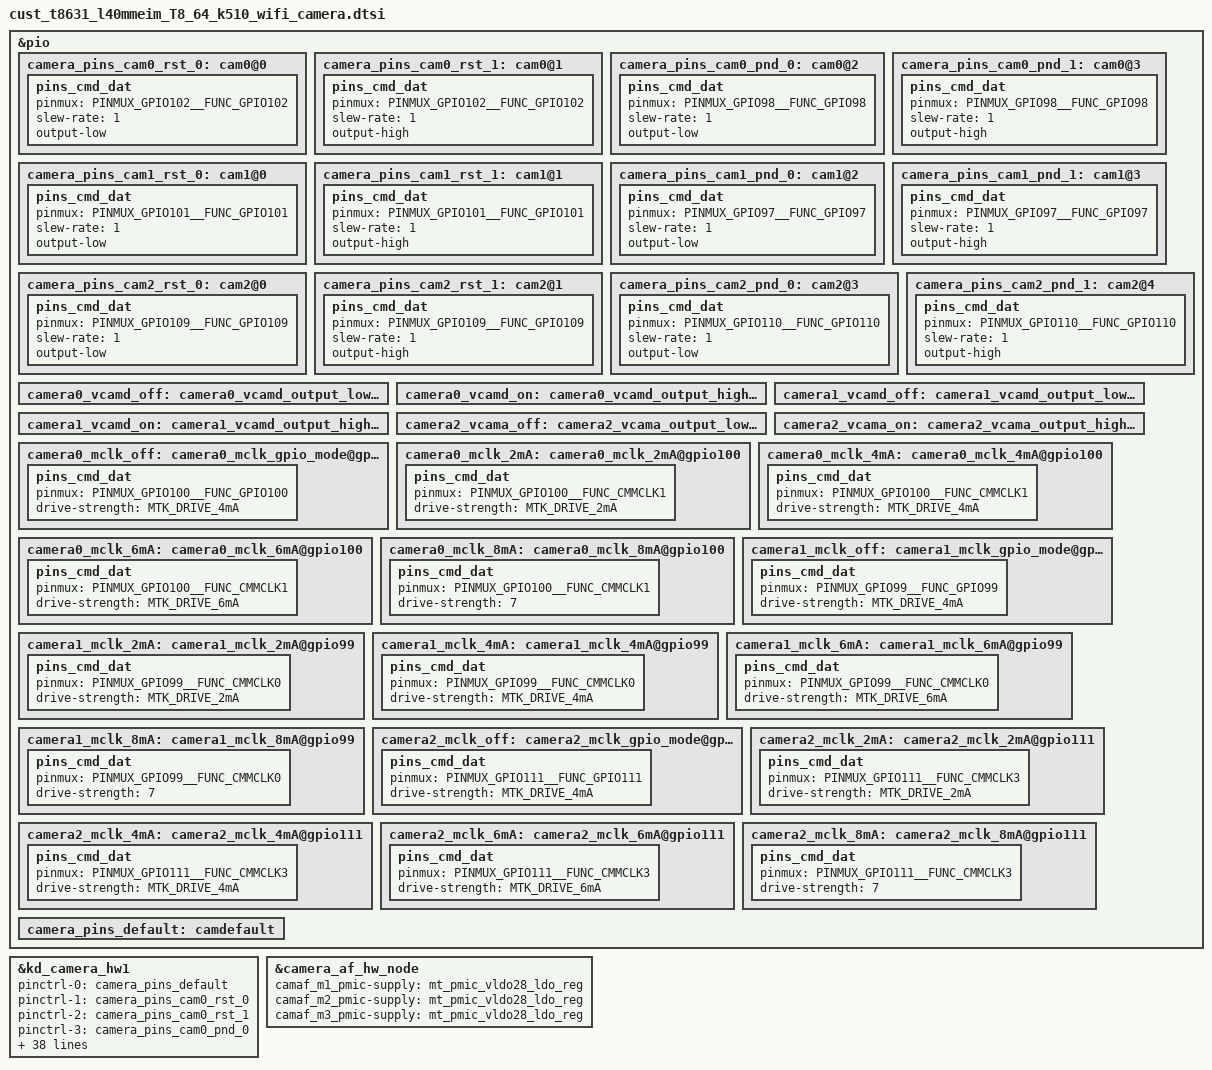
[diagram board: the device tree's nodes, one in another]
// SPDX-License-Identifier: (GPL-2.0 OR MIT)
/*
 * Copyright (c) 2019 MediaTek Inc.
 */
/* CAMERA GPIO standardization */
&pio {
	camera_pins_cam0_rst_0: cam0@0 {
		pins_cmd_dat {
			pinmux = <PINMUX_GPIO102__FUNC_GPIO102>;
			slew-rate = <1>;
			output-low;
		};
	};
	camera_pins_cam0_rst_1: cam0@1 {
		pins_cmd_dat {
			pinmux = <PINMUX_GPIO102__FUNC_GPIO102>;
			slew-rate = <1>;
			output-high;
		};
	};
	camera_pins_cam0_pnd_0: cam0@2 {
		pins_cmd_dat {
			pinmux = <PINMUX_GPIO98__FUNC_GPIO98>;
			slew-rate = <1>;
			output-low;
		};
	};
	camera_pins_cam0_pnd_1: cam0@3 {
		pins_cmd_dat {
			pinmux = <PINMUX_GPIO98__FUNC_GPIO98>;
			slew-rate = <1>;
			output-high;
		};
	};
	camera_pins_cam1_rst_0: cam1@0 {
		pins_cmd_dat {
			pinmux = <PINMUX_GPIO101__FUNC_GPIO101>;
			slew-rate = <1>;
			output-low;
		};
	};
	camera_pins_cam1_rst_1: cam1@1 {
		pins_cmd_dat {
			pinmux = <PINMUX_GPIO101__FUNC_GPIO101>;
			slew-rate = <1>;
			output-high;
		};
	};
	camera_pins_cam1_pnd_0: cam1@2 {
		pins_cmd_dat {
			pinmux = <PINMUX_GPIO97__FUNC_GPIO97>;
			slew-rate = <1>;
			output-low;
		};
	};
	camera_pins_cam1_pnd_1: cam1@3 {
		pins_cmd_dat {
			pinmux = <PINMUX_GPIO97__FUNC_GPIO97>;
			slew-rate = <1>;
			output-high;
		};
	};
	camera_pins_cam2_rst_0: cam2@0 {
		pins_cmd_dat {
			pinmux = <PINMUX_GPIO109__FUNC_GPIO109>;
			slew-rate = <1>;
			output-low;
		};
		
	};
	camera_pins_cam2_rst_1: cam2@1 {
		pins_cmd_dat {
			pinmux = <PINMUX_GPIO109__FUNC_GPIO109>;
			slew-rate = <1>;
			output-high;
		};
	
	};
	camera_pins_cam2_pnd_0: cam2@3 {
		pins_cmd_dat {
			pinmux = <PINMUX_GPIO110__FUNC_GPIO110>;
			slew-rate = <1>;
			output-low;
		};
	};
	camera_pins_cam2_pnd_1: cam2@4 {
		pins_cmd_dat {
			pinmux = <PINMUX_GPIO110__FUNC_GPIO110>;
			slew-rate = <1>;
			output-high;
		};
	};
	//
	
	
	camera0_vcamd_off: camera0_vcamd_output_low@gpio178 {
		//pins_cmd_dat {
			//pinmux = <PINMUX_GPIO178__FUNC_GPIO178>;
			//output-low;
		//};
	};
	camera0_vcamd_on: camera0_vcamd_output_high@gpio178 {
		//pins_cmd_dat {
			//pinmux = <PINMUX_GPIO178__FUNC_GPIO178>;
			//output-high;
		//};
	};
	camera1_vcamd_off: camera1_vcamd_output_low@gpio179 {
		//pins_cmd_dat {
			//pinmux = <PINMUX_GPIO179__FUNC_GPIO179>;
			//output-low;
		//};
	};
	camera1_vcamd_on: camera1_vcamd_output_high@gpio179 {
		//pins_cmd_dat {
			//pinmux = <PINMUX_GPIO179__FUNC_GPIO179>;
			//output-high;
		//};
	};
	camera2_vcama_off: camera2_vcama_output_low@gpio107 {
		//pins_cmd_dat {
			//pinmux = <PINMUX_GPIO107__FUNC_GPIO107>;
			//output-low;
		//};
	};
	camera2_vcama_on: camera2_vcama_output_high@gpio107 {
		//pins_cmd_dat {
			//pinmux = <PINMUX_GPIO107__FUNC_GPIO107>;
			//output-high;
		//};
	};
	
	
	//
	camera0_mclk_off: camera0_mclk_gpio_mode@gpio100 {
		pins_cmd_dat {
			pinmux = <PINMUX_GPIO100__FUNC_GPIO100>;
			drive-strength = <MTK_DRIVE_4mA>;
		};
	};
	camera0_mclk_2mA: camera0_mclk_2mA@gpio100 {
		pins_cmd_dat {
			pinmux = <PINMUX_GPIO100__FUNC_CMMCLK1>;
			drive-strength = <MTK_DRIVE_2mA>;
		};
	};
	camera0_mclk_4mA: camera0_mclk_4mA@gpio100 {
		pins_cmd_dat {
			pinmux = <PINMUX_GPIO100__FUNC_CMMCLK1>;
			drive-strength = <MTK_DRIVE_4mA>;
		};
	};
	camera0_mclk_6mA: camera0_mclk_6mA@gpio100 {
		pins_cmd_dat {
			pinmux = <PINMUX_GPIO100__FUNC_CMMCLK1>;
			drive-strength = <MTK_DRIVE_6mA>;
		};
	};
	camera0_mclk_8mA: camera0_mclk_8mA@gpio100 {
		pins_cmd_dat {
			pinmux = <PINMUX_GPIO100__FUNC_CMMCLK1>;
			drive-strength = <7>;
		};
	};
	//
	camera1_mclk_off: camera1_mclk_gpio_mode@gpio99 {
		pins_cmd_dat {
			pinmux = <PINMUX_GPIO99__FUNC_GPIO99>;
			drive-strength = <MTK_DRIVE_4mA>;
		};
	};
	camera1_mclk_2mA: camera1_mclk_2mA@gpio99 {
		pins_cmd_dat {
			pinmux = <PINMUX_GPIO99__FUNC_CMMCLK0>;
			drive-strength = <MTK_DRIVE_2mA>;
		};
	};
	camera1_mclk_4mA: camera1_mclk_4mA@gpio99 {
		pins_cmd_dat {
			pinmux = <PINMUX_GPIO99__FUNC_CMMCLK0>;
			drive-strength = <MTK_DRIVE_4mA>;
		};
	};
	camera1_mclk_6mA: camera1_mclk_6mA@gpio99 {
		pins_cmd_dat {
			pinmux = <PINMUX_GPIO99__FUNC_CMMCLK0>;
			drive-strength = <MTK_DRIVE_6mA>;
		};
	};
	camera1_mclk_8mA: camera1_mclk_8mA@gpio99 {
		pins_cmd_dat {
			pinmux = <PINMUX_GPIO99__FUNC_CMMCLK0>;
			drive-strength = <7>;
		};
	};
	//
	camera2_mclk_off: camera2_mclk_gpio_mode@gpio111 {
		pins_cmd_dat {
			pinmux = <PINMUX_GPIO111__FUNC_GPIO111>;
			drive-strength = <MTK_DRIVE_4mA>;
		};
	};
	camera2_mclk_2mA: camera2_mclk_2mA@gpio111 {
		pins_cmd_dat {
			pinmux = <PINMUX_GPIO111__FUNC_CMMCLK3>;
			drive-strength = <MTK_DRIVE_2mA>;
		};
	};
	camera2_mclk_4mA: camera2_mclk_4mA@gpio111 {
		pins_cmd_dat {
			pinmux = <PINMUX_GPIO111__FUNC_CMMCLK3>;
			drive-strength = <MTK_DRIVE_4mA>;
		};
	};
	camera2_mclk_6mA: camera2_mclk_6mA@gpio111 {
		pins_cmd_dat {
			pinmux = <PINMUX_GPIO111__FUNC_CMMCLK3>;
			drive-strength = <MTK_DRIVE_6mA>;
		};
	};
	camera2_mclk_8mA: camera2_mclk_8mA@gpio111 {
		pins_cmd_dat {
			pinmux = <PINMUX_GPIO111__FUNC_CMMCLK3>;
			drive-strength = <7>;
		};
	};	
	//	
	camera_pins_default: camdefault {
	};

};

&kd_camera_hw1 {
	pinctrl-names = "default",
			"cam0_rst0", "cam0_rst1",
			"cam0_pnd0", "cam0_pnd1",
			"cam1_rst0", "cam1_rst1",
			"cam1_pnd0", "cam1_pnd1",
			"cam2_rst0", "cam2_rst1",
			"cam2_pnd0", "cam2_pnd1",
			"cam0_vcamd_on",
			"cam0_vcamd_off",
			"cam1_vcamd_on",
			"cam1_vcamd_off",
			"cam2_vcama_on",
			"cam2_vcama_off",
			"cam0_mclk_off",
			"cam0_mclk_2mA", "cam0_mclk_4mA",
			"cam0_mclk_6mA", "cam0_mclk_8mA",
			"cam1_mclk_off",
			"cam1_mclk_2mA", "cam1_mclk_4mA",
			"cam1_mclk_6mA", "cam1_mclk_8mA",
			"cam2_mclk_off",
			"cam2_mclk_2mA", "cam2_mclk_4mA",
			"cam2_mclk_6mA", "cam2_mclk_8mA";

	pinctrl-0 = <&camera_pins_default>;
	pinctrl-1 = <&camera_pins_cam0_rst_0>;
	pinctrl-2 = <&camera_pins_cam0_rst_1>;
	pinctrl-3 = <&camera_pins_cam0_pnd_0>;
	pinctrl-4 = <&camera_pins_cam0_pnd_1>;
	pinctrl-5 = <&camera_pins_cam1_rst_0>;
	pinctrl-6 = <&camera_pins_cam1_rst_1>;
	pinctrl-7 = <&camera_pins_cam1_pnd_0>;
	pinctrl-8 = <&camera_pins_cam1_pnd_1>;
	pinctrl-9 = <&camera_pins_cam2_rst_0>;
	pinctrl-10 = <&camera_pins_cam2_rst_1>;
	pinctrl-11 = <&camera_pins_cam2_pnd_0>;
	pinctrl-12 = <&camera_pins_cam2_pnd_1>;
	
	pinctrl-13 = <&camera0_vcamd_off>;
	pinctrl-14 = <&camera0_vcamd_on>;	
	pinctrl-15 = <&camera1_vcamd_off>;
	pinctrl-16 = <&camera1_vcamd_on>;
	pinctrl-17 = <&camera2_vcama_off>;
	pinctrl-18 = <&camera2_vcama_on>;
	
	
	pinctrl-19 = <&camera0_mclk_off>;
	pinctrl-20 = <&camera0_mclk_2mA>;
	pinctrl-21 = <&camera0_mclk_4mA>;
	pinctrl-22 = <&camera0_mclk_6mA>;
	pinctrl-23 = <&camera0_mclk_8mA>;
	
	pinctrl-24 = <&camera1_mclk_off>;
	pinctrl-25 = <&camera1_mclk_2mA>;
	pinctrl-26 = <&camera1_mclk_4mA>;
	pinctrl-27 = <&camera1_mclk_6mA>;
	pinctrl-28 = <&camera1_mclk_8mA>;
	
	pinctrl-29 = <&camera2_mclk_off>;
	pinctrl-30 = <&camera2_mclk_2mA>;
	pinctrl-31 = <&camera2_mclk_4mA>;
	pinctrl-32 = <&camera2_mclk_6mA>;
	pinctrl-33 = <&camera2_mclk_8mA>;
	/*
	cam0_vcama-supply = <&mt_pmic_vcama1_ldo_reg>;
	cam1_vcama-supply = <&mt_pmic_vcama2_ldo_reg>;
	cam2_vcamd-supply = <&mt_pmic_vcamd_ldo_reg>;
	
	cam0_vcamio-supply = <&mt_pmic_vcamio_ldo_reg>;
	cam1_vcamio-supply = <&mt_pmic_vcamio_ldo_reg>;
	cam2_vcamio-supply = <&mt_pmic_vcamio_ldo_reg>;
	*/
	//
	//VCAMIO_PMU DVIO18 cam0 --ok
	//VCAMA2_PMU AVDD28 cam0 --ok
	//VCAMD_PMU  DVDD12 cam0 --ok
	cam0_vcama-supply = <&mt_pmic_vcama2_ldo_reg>;
	cam0_vcamio-supply = <&mt_pmic_vcamio_ldo_reg>;
	cam0_vcamd-supply = <&mt_pmic_vcamd_ldo_reg>;
	
	cam1_vcama-supply = <&mt_pmic_vcama1_ldo_reg>;
	cam1_vcamio-supply = <&mt_pmic_vcamio_ldo_reg>;
	cam1_vcamd-supply = <&mt_pmic_vcamd_ldo_reg>;
	
			
	//cam2_vcamio-supply = <&mt_pmic_vcamio_ldo_reg>;

	cam0_enable_sensor = "ov13850_mipi_raw ";
	cam1_enable_sensor = "gc05a2_mipi_raw";
	
	status = "okay";

};
/* CAMERA GPIO end */

/* CAMERA AF */
&camera_af_hw_node {
	camaf_m1_pmic-supply = <&mt_pmic_vldo28_ldo_reg>;
	camaf_m2_pmic-supply = <&mt_pmic_vldo28_ldo_reg>;
	camaf_m3_pmic-supply = <&mt_pmic_vldo28_ldo_reg>;
	status = "okay";
};
/* CAMERA AF end */
